# STM32F446xx register map
File version: 1.0
Registers are 32-bit, read-write, reset 0x0 unless marked. A register's access mark holds for its fields unless they carry their own. Offsets are from the block's base; [hi:lo] are bit positions; {n}, {i} and the like mark numbered series.

## SPDIFRX — SPDIFRX Interface
Base 0x40004000
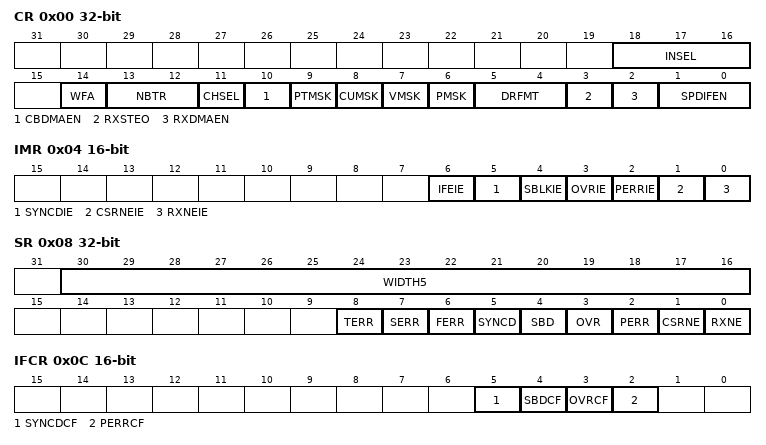
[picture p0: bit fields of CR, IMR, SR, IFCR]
0x00 CR — Control register
  [18:16] INSEL — SPDIFRX input selection
  [14] WFA — Wait For Activity
  [13:12] NBTR — Maximum allowed re-tries during synchronization phase
  [11] CHSEL — Channel Selection
  [10] CBDMAEN — Control Buffer DMA ENable for control flow
  [9] PTMSK — Mask of Preamble Type bits
  [8] CUMSK — Mask of channel status and user bits
  [7] VMSK — Mask of Validity bit
  [6] PMSK — Mask Parity error bit
  [5:4] DRFMT — RX Data format
  [3] RXSTEO — Stereo Mode
  [2] RXDMAEN — Receiver DMA Enable for data flow
  [1:0] SPDIFEN — Peripheral Block Enable
0x04 IMR 16-bit — Interrupt mask register
  [6] IFEIE — Serial Interface Error Interrupt Enable
  [5] SYNCDIE — Synchronization Done
  [4] SBLKIE — Synchronization Block Detected Interrupt Enable
  [3] OVRIE — Overrun error Interrupt Enable
  [2] PERRIE — Parity error interrupt enable
  [1] CSRNEIE — Control Buffer Ready Interrupt Enable
  [0] RXNEIE — RXNE interrupt enable
0x08 SR — Status register
  [30:16] WIDTH5 — Duration of 5 symbols counted with SPDIFRX_clk
  [8] TERR — Time-out error
  [7] SERR — Synchronization error
  [6] FERR — Framing error
  [5] SYNCD — Synchronization Done
  [4] SBD — Synchronization Block Detected
  [3] OVR — Overrun error
  [2] PERR — Parity error
  [1] CSRNE — The Control Buffer register is not empty
  [0] RXNE — Read data register not empty
0x0C IFCR 16-bit — Interrupt Flag Clear register
  [5] SYNCDCF — Clears the Synchronization Done flag
  [4] SBDCF — Clears the Synchronization Block Detected flag
  [3] OVRCF — Clears the Overrun error flag
  [2] PERRCF — Clears the Parity error flag
0x10 DR — Data input register
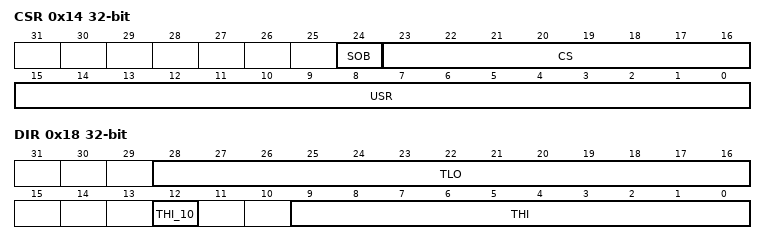
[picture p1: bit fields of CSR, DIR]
0x14 CSR — Channel Status register
  [24] SOB — Start Of Block
  [23:16] CS — Channel A status information
  [15:0] USR — User data information
0x18 DIR — Debug Information register
  [28:16] TLO — Threshold HIGH
  [12] THI_10 — Threshold LOW
  [9:0] THI — Threshold LOW

## I2C1 — Inter-integrated Circuit Interface
Base 0x40005400
Same registers: I2C2 0x40005800, I2C3 0x40005C00
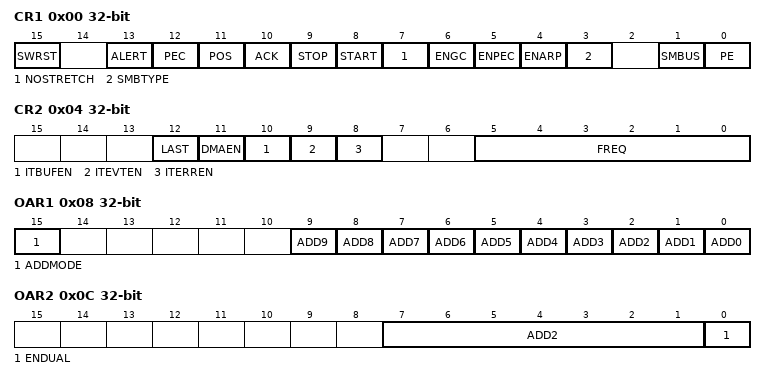
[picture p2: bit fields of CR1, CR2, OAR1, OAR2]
0x00 CR1 — I2C Control register 1
  [15] SWRST — Software Reset
  [13] ALERT — SMBus Alert
  [12] PEC — Packet Error Checking
  [11] POS — Acknowledge/PEC Position (for data reception)
  [10] ACK — Acknowledge Enable
    1=ACK (ACK is sent after current received byte.); 0=NACK (NACK is sent after current received byte.)
  [9] STOP — Stop Generation
  [8] START — Start Generation
  [7] NOSTRETCH — Clock Stretching Disable (Slave mode)
  [6] ENGC — General Call Enable
  [5] ENPEC — PEC Enable
  [4] ENARP — ARP Enable
  [3] SMBTYPE — SMBus Type
  [1] SMBUS — SMBus Mode
  [0] PE — Peripheral Enable
0x04 CR2 — I2C Control register 2
  [12] LAST — DMA Last Transfer
  [11] DMAEN — DMA Requests Enable
  [10] ITBUFEN — Buffer Interrupt Enable
  [9] ITEVTEN — Event Interrupt Enable
  [8] ITERREN — Error Interrupt Enable
  [5:0] FREQ — FREQ[5:0] bits (Peripheral Clock Frequency)
0x08 OAR1 — I2C Own address register 1
  [15] ADDMODE — Addressing Mode (Slave mode)
  [n] ADD{n} (n=0..9) — Bit {n}
0x0C OAR2 — I2C Own address register 2
  [7:1] ADD2 — Interface address
  [0] ENDUAL — Dual addressing mode enable
0x10 DR — I2C Data register
  [7:0] DR — 8-bit Data Register
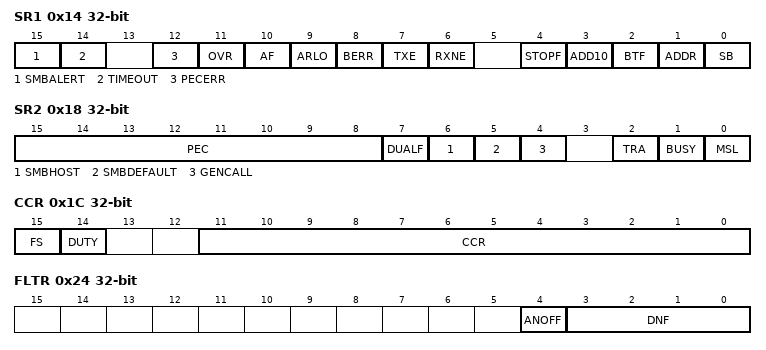
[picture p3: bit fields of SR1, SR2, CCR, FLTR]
0x14 SR1 — I2C Status register 1
  [15] SMBALERT — SMBus Alert
  [14] TIMEOUT — Timeout or Tlow Error
  [12] PECERR — PEC Error in reception
  [11] OVR — Overrun/Underrun
  [10] AF — Acknowledge Failure
  [9] ARLO — Arbitration Lost (master mode)
  [8] BERR — Bus Error
  [7] TXE — Data Register Empty (transmitters)
  [6] RXNE — Data Register not Empty (receivers)
  [4] STOPF — Stop detection (Slave mode)
  [3] ADD10 — 10-bit header sent (Master mode)
  [2] BTF — Byte Transfer Finished
  [1] ADDR — Address sent (master mode)/matched (slave mode)
  [0] SB — Start Bit (Master mode)
0x18 SR2 — I2C Status register 2
  [15:8] PEC — Packet Error Checking Register
  [7] DUALF — Dual Flag (Slave mode)
  [6] SMBHOST — SMBus Host Header (Slave mode)
  [5] SMBDEFAULT — SMBus Device Default Address (Slave mode)
  [4] GENCALL — General Call Address (Slave mode)
  [2] TRA — Transmitter/Receiver
    1=WRITE (Bus is in write transfer); 0=READ (Bus is in read transfer)
  [1] BUSY — Bus Busy
  [0] MSL — Master/Slave
0x1C CCR — I2C Clock control register
  [15] FS — I2C Master Mode Selection
    0=STANDARD_MODE (Master clock speed range is standard mode); 1=FAST_MODE (Master clock speed range is fast mode)
  [14] DUTY — Fast Mode Duty Cycle
    0=DUTYCYCLE_2 (I2C fast mode Tlow/Thigh = 2); 1=DUTYCYCLE_16_9 (I2C fast mode Tlow/Thigh = 16/9)
  [11:0] CCR — Clock Control Register in Fast/Standard mode (Master mode)
0x20 TRISE — I2C TRISE register
  [5:0] TRISE — Maximum Rise Time in Fast/Standard mode (Master mode)
0x24 FLTR — I2C FLTR register
  [4] ANOFF — Analog Noise Filter OFF
  [3:0] DNF — Digital Noise Filter
